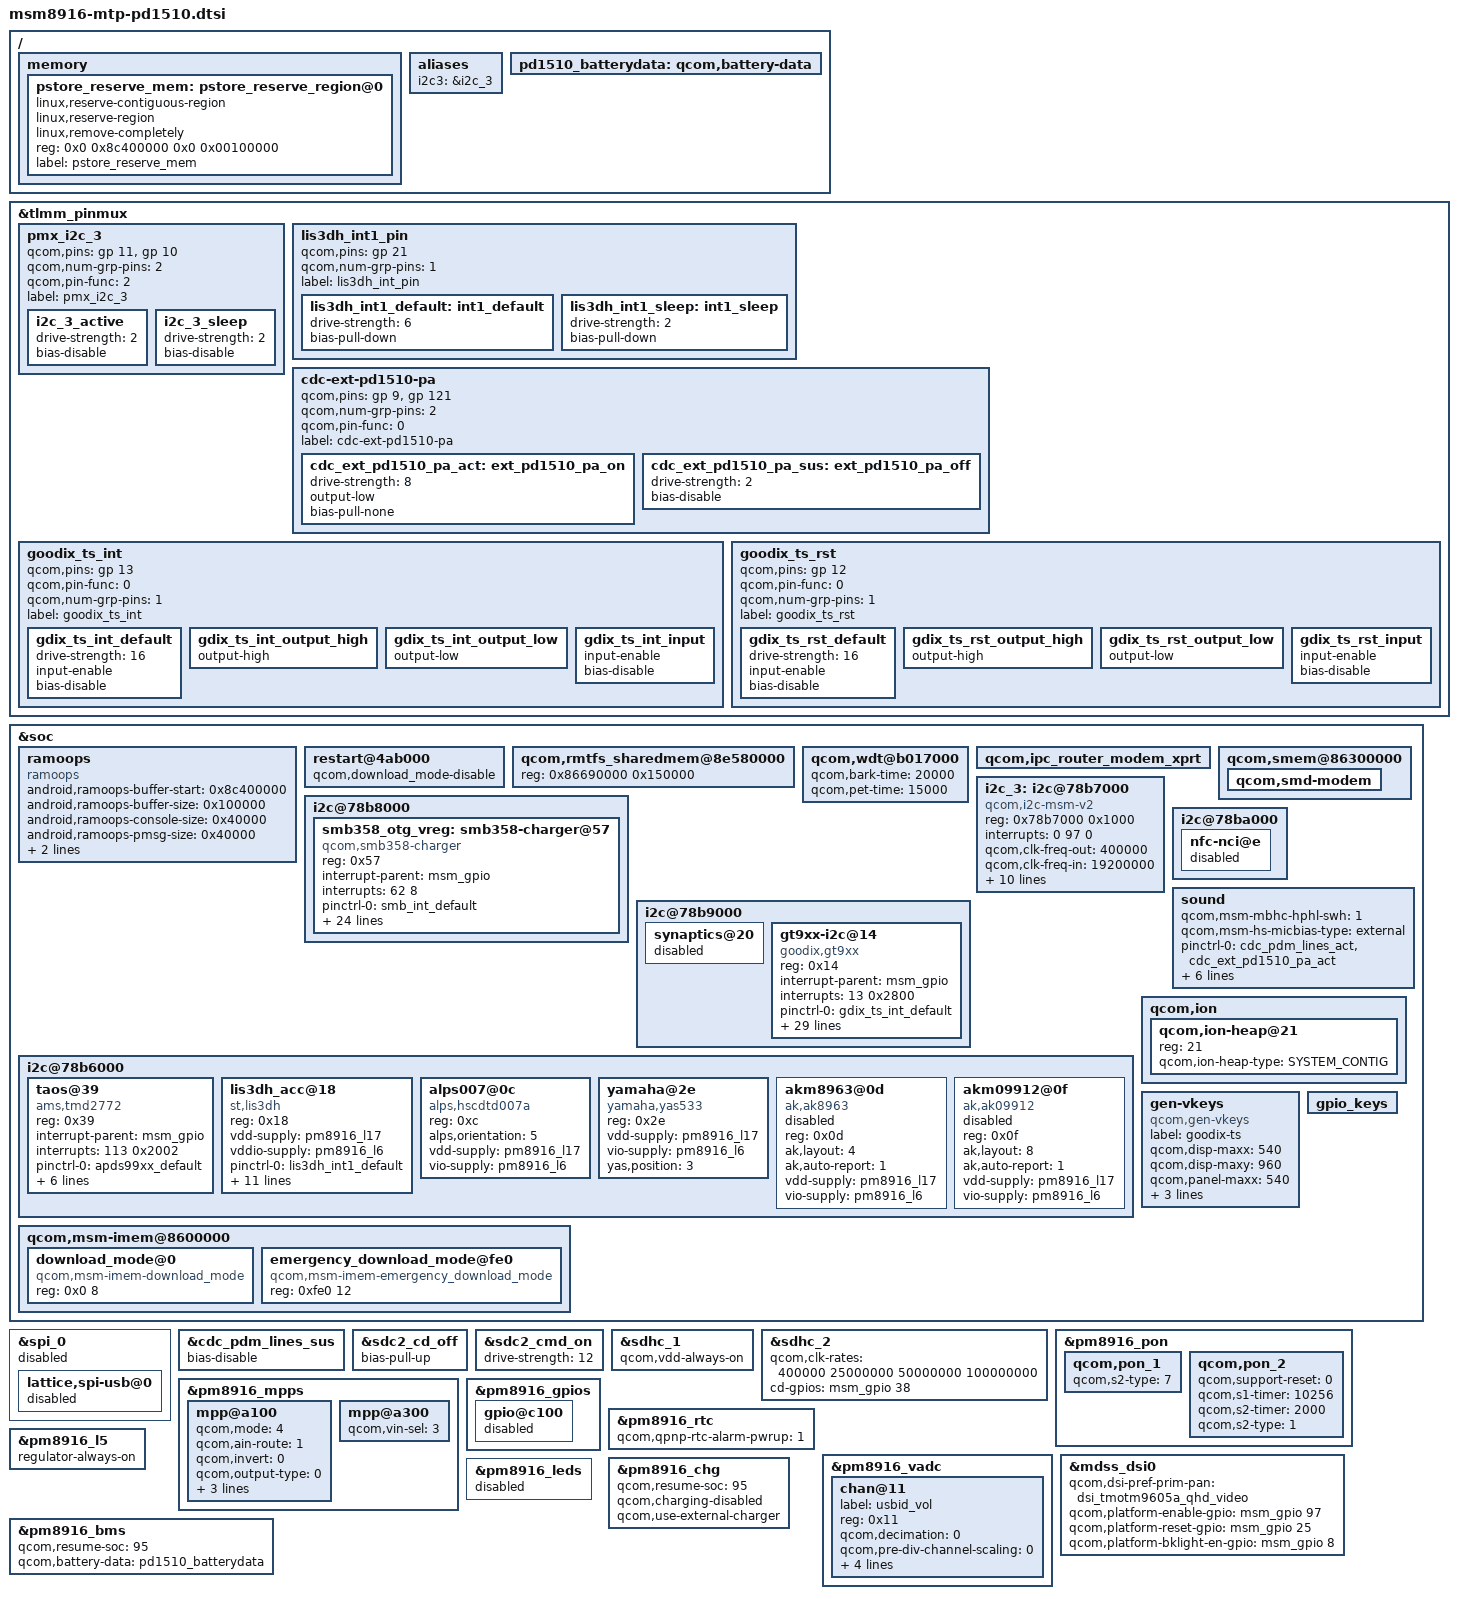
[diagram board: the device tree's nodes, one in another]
/*
 * Copyright (c) 2014-2018, The Linux Foundation. All rights reserved.
 *
 * This program is free software; you can redistribute it and/or modify
 * it under the terms of the GNU General Public License version 2 and
 * only version 2 as published by the Free Software Foundation.
 *
 * This program is distributed in the hope that it will be useful,
 * but WITHOUT ANY WARRANTY; without even the implied warranty of
 * MERCHANTABILITY or FITNESS FOR A PARTICULAR PURPOSE.  See the
 * GNU General Public License for more details.
 */

#include "dsi-panel-tmotm9605a-qhd-video.dtsi"
#include "msm8916-camera-sensor-mtp-pd1510.dtsi"

/ {
	memory {
		pstore_reserve_mem: pstore_reserve_region@0 {
			linux,reserve-contiguous-region;
			linux,reserve-region;
			linux,remove-completely;
			reg = <0x0 0x8c400000 0x0 0x00100000>;
			label = "pstore_reserve_mem";
		};
	};

	aliases {
		i2c3 = &i2c_3; /* I2C3 controller device */
	};
};

&tlmm_pinmux {
	pmx_i2c_3 {
		/* CLK, DATA */
		qcom,pins = <&gp 11>, <&gp 10>;
		qcom,num-grp-pins = <2>;
		qcom,pin-func = <2>;
		label = "pmx_i2c_3";

		i2c_3_active: i2c_3_active {
			drive-strength = <2>; /* 2 MA */
			bias-disable;		  /* No PULL */
		};

		i2c_3_sleep: i2c_3_sleep {
			drive-strength = <2>; /* 2 MA */
			bias-disable;		  /* No PULL */
		};
	};

	lis3dh_int1_pin {
		qcom,pins = <&gp 21>;
		qcom,num-grp-pins = <1>;
		label = "lis3dh_int_pin";
		lis3dh_int1_default: int1_default {
			drive-strength = <6>;
			bias-pull-down;
		};
		lis3dh_int1_sleep: int1_sleep {
			drive-strength = <2>;
			bias-pull-down;
		};
	};

	cdc-ext-pd1510-pa {
		qcom,pins = <&gp 9>, <&gp 121>;
		qcom,num-grp-pins = <2>;
		qcom,pin-func = <0>;
		label = "cdc-ext-pd1510-pa";
		cdc_ext_pd1510_pa_act: ext_pd1510_pa_on {
			drive-strength = <8>;
			output-low;
			bias-pull-none;
		};
		cdc_ext_pd1510_pa_sus: ext_pd1510_pa_off {
			drive-strength = <2>;
			bias-disable;
		};
	};

	goodix_ts_int {
		qcom,pins = <&gp 13>;
		qcom,pin-func = <0>;
		qcom,num-grp-pins = <1>;
		label = "goodix_ts_int";

		gdix_ts_int_default: gdix_ts_int_default {
			drive-strength = <16>;
			input-enable;
			bias-disable;
		};

		gdix_ts_int_output_high: gdix_ts_int_output_high {
			output-high;
		};

		gdix_ts_int_output_low: gdix_ts_int_output_low {
			output-low;
		};

		gdix_ts_int_input: gdix_ts_int_input {
			input-enable;
			bias-disable;
		};
	};

	goodix_ts_rst {
		qcom,pins = <&gp 12>;
		qcom,pin-func = <0>;
		qcom,num-grp-pins = <1>;
		label = "goodix_ts_rst";

		gdix_ts_rst_default: gdix_ts_rst_default {
			drive-strength = <16>;
			input-enable;
			bias-disable;
		};

		gdix_ts_rst_output_high: gdix_ts_rst_output_high {
			output-high;
		};

		gdix_ts_rst_output_low: gdix_ts_rst_output_low {
			output-low;
		};

		gdix_ts_rst_input: gdix_ts_rst_input {
			input-enable;
			bias-disable;
		};
	};
};

&soc {
	ramoops {
		compatible = "ramoops";
		status = "ok";

		android,ramoops-buffer-start = <0x8c400000>;
		android,ramoops-buffer-size = <0x100000>;
		android,ramoops-console-size = <0x40000>;
		android,ramoops-pmsg-size = <0x40000>;
		android,ramoops-record-size = <0x20000>;
		android,ramoops-dump-oops = <0x1>;
	};

	restart@4ab000 {
		qcom,download_mode-disable;
	};

	qcom,rmtfs_sharedmem@8e580000 {
		reg = <0x86690000 0x150000>;
	};

	qcom,wdt@b017000 {
		qcom,bark-time = <20000>;
		qcom,pet-time = <15000>;
	};

	qcom,ipc_router_modem_xprt {
		/delete-property/ qcom,disable-pil-loading;
	};

	qcom,smem@86300000 {
		qcom,smd-modem {
			/delete-property/ qcom,not-loadable;
		};
	};

	i2c@78b8000 {
		smb358_otg_vreg: smb358-charger@57 {
			compatible = "qcom,smb358-charger";
			reg = <0x57>;
			interrupt-parent = <&msm_gpio>;
			interrupts = <62 8>;
			pinctrl-names = "default";
			pinctrl-0 = <&smb_int_default>;

			qcom,float-voltage-mv = <4360>;
			qcom,recharge-mv = <100>;
			qcom,recharge-disabled;
			regulator-name = "smb358_otg_vreg";
			qcom,thermal-mitigation = <1300 700 600 0>;
			qcom,fastchg-current-max-ma = <1300>;

			qcom,disable-apsd;
			qcom,bms-psy-name = "bms";
			/* qcom,iterm-disabled; */
			qcom,iterm-ma = <150>;
			qcom,bms-controlled-charging;
			qcom,chg-inhibit-disabled;
			qcom,chg-vadc = <&pm8916_vadc>;
			qcom,chg-adc_tm = <&pm8916_adc_tm>;
			/* qcom,vcc-i2c-supply = <&pm8916_l5>; */
			qcom,irq-gpio = <&msm_gpio 62 0x00>;

			qcom,using-pmic-therm;
			qcom,hot-bat-decidegc = <550>;
			qcom,cold-bat-decidegc = <0>;
			qcom,bat-present-decidegc = <200>;
			/*
			 * Below properties are used for enable JEITA
			 */
			qcom,warm-bat-decidegc = <450>;
			qcom,cool-bat-decidegc = <0>;
			qcom,warm-bat-ma = <1000>;
			qcom,cool-bat-ma = <1000>;
			qcom,warm-bat-mv = <4000>;
			qcom,cool-bat-mv = <4000>;
			status = "ok";
		};
	};

	i2c_3: i2c@78b7000 { /* BLSP1 QUP3 */
		compatible = "qcom,i2c-msm-v2";
		#address-cells = <1>;
		#size-cells = <0>;
		reg-names = "qup_phys_addr";
		reg = <0x78b7000 0x1000>;
		interrupt-names = "qup_irq";
		interrupts = <0 97 0>;
		qcom,clk-freq-out = <400000>;
		qcom,clk-freq-in  = <19200000>;
		clock-names = "iface_clk", "core_clk";
		clocks = <&clock_gcc clk_gcc_blsp1_ahb_clk>,
			<&clock_gcc clk_gcc_blsp1_qup3_i2c_apps_clk>;
		qcom,use-pinctrl;
		pinctrl-names = "i2c_active", "i2c_sleep";
		pinctrl-0 = <&i2c_3_active>;
		pinctrl-1 = <&i2c_3_sleep>;
		qcom,noise-rjct-scl = <0>;
		qcom,noise-rjct-sda = <0>;
		dmas = <&dma_blsp1 8 64 0x20000020 0x20>,
			<&dma_blsp1 9 32 0x20000020 0x20>;
		dma-names = "tx", "rx";
		qcom,master-id = <86>;
	};

	i2c@78b9000 { /* BLSP1 QUP5 */
		synaptics@20 {
			status = "disabled";
		};

		gt9xx-i2c@14 {
			compatible = "goodix,gt9xx";
			reg = <0x14>;
			interrupt-parent = <&msm_gpio>;
			interrupts = <13 0x2800>;
			pinctrl-names = "gdix_ts_int_default",
				"gdix_ts_int_output_low",
				"gdix_ts_int_output_high",
				"gdix_ts_int_input",
				"gdix_ts_rst_default",
				"gdix_ts_rst_output_low",
				"gdix_ts_rst_output_high",
				"gdix_ts_rst_input";
			pinctrl-0 = <&gdix_ts_int_default>;
			pinctrl-1 = <&gdix_ts_int_output_low>;
			pinctrl-2 = <&gdix_ts_int_output_high>;
			pinctrl-3 = <&gdix_ts_int_input>;
			pinctrl-4 = <&gdix_ts_rst_default>;
			pinctrl-5 = <&gdix_ts_rst_output_low>;
			pinctrl-6 = <&gdix_ts_rst_output_high>;
			pinctrl-7 = <&gdix_ts_rst_input>;
			reset-gpios = <&msm_gpio 12 0x00>;
			irq-gpios = <&msm_gpio 13 0x2800>;
			irq-flags = <1>;
			vdd_ana-supply = <&pm8916_l16>;
			vcc_i2c-supply = <&pm8916_l6>;
			touchscreen-max-id = <11>;
			touchscreen-size-x = <540>;
			touchscreen-size-y = <960>;
			touchscreen-max-w = <512>;
			touchscreen-max-p = <512>;
			touchscreen-key-map = <158>, <102>, <139>; /*KEY_BACK=158，KEY_HOMEPAGE=102, KEY_MENU=139*/
			goodix,slide-wakeup = <1>;
			goodix,type-a-report = <0>;
			goodix,driver-send-cfg = <1>;
			goodix,resume-in-workqueue = <0>;
			goodix,int-sync = <1>;
			goodix,swap-x2y = <0>;
			goodix,esd-protect = <1>;
			goodix,auto-update = <0>;
			goodix,auto-update-cfg = <0>;
			goodix,power-off-sleep = <0>;
			goodix,pen-suppress-finger = <0>;
		};
	};

	i2c@78ba000 { /* BLSP1 QUP6 */
		status = "okay";

		nfc-nci@e {
			status = "disabled";
		};
	};

	i2c@78b6000 { /* BLSP1 QUP2 */
		/delete-node/ mpu6050@68;
		/delete-node/ avago@39;
		/delete-node/ akm@c;

		taos@39 {
			compatible = "ams,tmd2772";
			reg = <0x39>;
			interrupt-parent = <&msm_gpio>;
			interrupts = <113 0x2002>;
			pinctrl-names = "tmd2772_default","tmd2772_sleep";
			pinctrl-0 = <&apds99xx_default>;
			pinctrl-1 = <&apds99xx_sleep>;
			vdd-supply = <&pm8916_l17>;
			vio-supply = <&pm8916_l6>;
			ams,irq-gpio = <&msm_gpio 113 0x2002>;
			ams,pul_cnt = <12>;
			ams,light-percent = <150>;
		};

		lis3dh_acc@18 {
			compatible = "st,lis3dh";
			reg = <0x18>;
			vdd-supply = <&pm8916_l17>;
			vddio-supply = <&pm8916_l6>;
			pinctrl-names = "lis3dh_default","lis3dh_sleep";
			pinctrl-0 = <&lis3dh_int1_default>;
			pinctrl-1 = <&lis3dh_int1_sleep>;
			interrupt-parent = <&msm_gpio>;
			interrupts = <21 0x0>;
			st,min-interval = <10>;
			st,init-interval = <200>;
			st,axis-map-x = <1>;
			st,axis-map-y = <0>;
			st,axis-map-z = <2>;
			st,g-range = <2>;
			/*st,negate-x;*/ /*Disabled boolean property*/
			st,negate-y; /*Enabled boolean property*/
			/*st,negate-z;*/ /*Disabled boolean property*/
			st,gpio-int1 = <&msm_gpio 21 0x2002>;
			/*status = "disabled";*/
		};

		alps007@0c {
			compatible = "alps,hscdtd007a";
			reg = <0xc>;
			alps,orientation = <5>;
			vdd-supply = <&pm8916_l17>;
			vio-supply = <&pm8916_l6>;
		};

		yamaha@2e {
			compatible = "yamaha,yas533";
			reg = <0x2e>;
			vdd-supply = <&pm8916_l17>;
			vio-supply = <&pm8916_l6>;
			yas,position = <3>;
		};

		akm8963@0d {
			compatible = "ak,ak8963";
			reg = <0x0d>;
			ak,layout = <4>;
			ak,auto-report = <1>;
			vdd-supply = <&pm8916_l17>;
			vio-supply = <&pm8916_l6>;
			status = "disabled";
		};

		akm09912@0f {
			compatible = "ak,ak09912";
			reg = <0x0f>;
			ak,layout = <8>;
			ak,auto-report = <1>;
			vdd-supply = <&pm8916_l17>;
			vio-supply = <&pm8916_l6>;
			status = "disabled";
		};

	};

	qcom,msm-imem@8600000 {
		download_mode@0 {
			compatible = "qcom,msm-imem-download_mode";
			reg = <0x0 8>;
		};

		emergency_download_mode@fe0 {
			compatible = "qcom,msm-imem-emergency_download_mode";
			reg = <0xfe0 12>;
		};
	};

	sound {
		qcom,msm-mbhc-hphl-swh = <1>;
		qcom,msm-hs-micbias-type = "external";
		pinctrl-names = "cdc_lines_act",
				"cdc_lines_sus",
				"cross_conn_det_act",
				"cross_conn_det_sus";
		pinctrl-0 = <&cdc_pdm_lines_act &cdc_ext_pd1510_pa_act>;
		pinctrl-1 = <&cdc_pdm_lines_sus &cdc_ext_pd1510_pa_sus>;
		pinctrl-2 = <&cross_conn_det_act>;
		pinctrl-3 = <&cross_conn_det_sus>;
		/delete-property/ pinctrl-4;
		/delete-property/ pinctrl-5;
		qcom,msm-spk-ext-pa = <&msm_gpio 121 0>;
		qcom,msm-hs-ext-pa = <&msm_gpio 9 0>;
	};

	qcom,ion {
		qcom,ion-heap@21 {
			reg = <21>;
			qcom,ion-heap-type = "SYSTEM_CONTIG";
		};
	};

	gen-vkeys {
		compatible = "qcom,gen-vkeys";
		label = "goodix-ts";
		qcom,disp-maxx = <540>;
		qcom,disp-maxy = <960>;
		qcom,panel-maxx = <540>;
		qcom,panel-maxy = <1031>;
		qcom,key-codes = <158 102 139>;
		qcom,y-offset = <0>;
	};

	gpio_keys {
		/delete-node/ camera_focus;
		/delete-node/ camera_snapshot;
	};
};

/* kumajaya: Completely disable spi0 and freeing gpio 902+9 */
&spi_0 {
	status = "disabled";

	lattice,spi-usb@0 {
		status = "disabled";
	};
};

&cdc_pdm_lines_sus {
	/delete-property/ bias-pull-down;
	bias-disable;
};

&sdc2_cd_off {
	/delete-property/ bias-disable;
	bias-pull-up;
};

&sdc2_cmd_on {
	drive-strength = <12>;
};

&sdhc_1 {
	qcom,vdd-always-on;
};

&sdhc_2 {
	qcom,clk-rates = <400000 25000000 50000000 100000000>;
	cd-gpios = <&msm_gpio 38 0x0>;
};

&pm8916_pon {
	qcom,pon_1 {
		qcom,s2-type = <7>;
	};

	qcom,pon_2 {
		qcom,support-reset = <0>;
		qcom,s1-timer = <10256>;
		qcom,s2-timer = <2000>;
		qcom,s2-type = <1>;
	};
};

&pm8916_mpps {
	mpp@a100 { /* MPP 2 */
		/* HR LED */
		status = "ok";
		qcom,mode = <4>;
		qcom,ain-route = <1>;
		qcom,invert = <0>;
		qcom,output-type = <0>;
		qcom,src-sel = <0>;
		qcom,vin-sel = <0>;
		qcom,master-en = <1>;
	};

	mpp@a300 { /* MPP 4 */
		/* Backlight PWM */
		qcom,vin-sel = <3>;
	};
};

&pm8916_gpios {
	gpio@c100 { /* GPIO 2 */
		status = "disabled";
	};
};

&pm8916_rtc {
	qcom,qpnp-rtc-alarm-pwrup = <1>;
};

&pm8916_vadc {
	chan@11 {
		label = "usbid_vol";
		reg = <0x11>;
		qcom,decimation = <0>;
		qcom,pre-div-channel-scaling = <0>;
		qcom,calibration-type = "absolute";
		qcom,scale-function = <0>;
		qcom,hw-settle-time = <0>;
		qcom,fast-avg-setup = <0>;
	};
};

&pm8916_l5 { /* For erratic touchscreen */
	regulator-always-on;
};

&mdss_dsi0 {
	qcom,dsi-pref-prim-pan = <&dsi_tmotm9605a_qhd_video>;
	qcom,platform-enable-gpio = <&msm_gpio 97 0>;
	qcom,platform-reset-gpio = <&msm_gpio 25 0>;
	qcom,platform-bklight-en-gpio = <&msm_gpio 8 0>;
};

/ {
	pd1510_batterydata: qcom,battery-data {
		/delete-node/ qcom,palladium-batterydata;

		#include "batterydata-b76-atl-4v35-2260mah.dtsi"
		#include "batterydata-desay-samsung-2260mah.dtsi"
		#include "batterydata-atl-ds-4v35-2300mah.dtsi"
		#include "batterydata-samsung-ds-4v35-2300mah.dtsi"
		#include "batterydata-atl-nvt-4v35-2300mah.dtsi"
	};
};

&pm8916_chg {
	status = "ok";
	qcom,resume-soc = <95>;
	qcom,charging-disabled;
	qcom,use-external-charger;
};

&pm8916_bms {
	status = "ok";
	qcom,resume-soc = <95>;
	qcom,battery-data = <&pd1510_batterydata>;
};

&pm8916_leds {
	status = "disabled";
};
